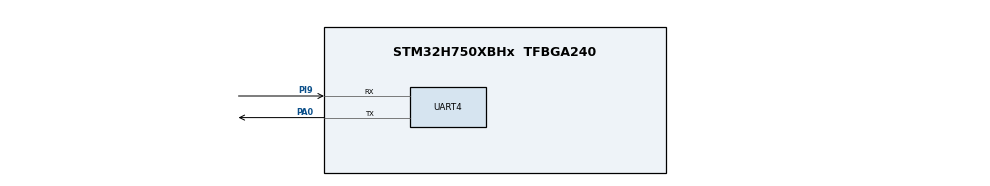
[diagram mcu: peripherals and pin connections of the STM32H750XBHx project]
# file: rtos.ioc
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FREERTOS.Tasks01=defaultTask,24,128,StartDefaultTask,Default,NULL,Dynamic,NULL,NULL
FREERTOS.configTICK_RATE_HZ=1000
FREERTOS.configUSE_NEWLIB_REENTRANT=1
Mcu.Family=STM32H7
Mcu.Name=STM32H750XBHx
Mcu.Package=TFBGA240
NVIC.PriorityGroup=NVIC_PRIORITYGROUP_4
NVIC.TIM6_DAC_IRQn=true\:15\:0\:false\:false\:true\:false\:false\:true\:true
NVIC.TimeBase=TIM6_DAC_IRQn
NVIC.TimeBaseIP=TIM6
NVIC.UART4_IRQn=true\:5\:0\:false\:false\:true\:true\:true\:true\:true
PA0.Mode=Asynchronous
PA0.Signal=UART4_TX
PA13\ (JTMS/SWDIO).Mode=Serial_Wire
PA13\ (JTMS/SWDIO).Signal=DEBUG_JTMS-SWDIO
PA14\ (JTCK/SWCLK).Mode=Serial_Wire
PA14\ (JTCK/SWCLK).Signal=DEBUG_JTCK-SWCLK
PH0-OSC_IN\ (PH0).Mode=HSE-External-Oscillator
PH0-OSC_IN\ (PH0).Signal=RCC_OSC_IN
PH1-OSC_OUT\ (PH1).Mode=HSE-External-Oscillator
PH1-OSC_OUT\ (PH1).Signal=RCC_OSC_OUT
PI9.Mode=Asynchronous
PI9.Signal=UART4_RX
ProjectManager.HeapSize=0x200
ProjectManager.StackSize=0x400
ProjectManager.TargetToolchain=STM32CubeIDE
RCC.ADCFreq_Value=400000000
RCC.APB1Freq_Value=100000000
RCC.APB2Freq_Value=100000000
RCC.APB3Freq_Value=100000000
RCC.APB4Freq_Value=100000000
RCC.CortexFreq_Value=400000000
RCC.D1PPRE=RCC_APB3_DIV2
RCC.D2PPRE1=RCC_APB1_DIV2
RCC.D2PPRE2=RCC_APB2_DIV2
RCC.D3PPRE=RCC_APB4_DIV2
RCC.DIVM1=5
RCC.DIVM2=5
RCC.DIVN1=160
RCC.DIVN2=160
RCC.DIVQ2=20
RCC.HCLKFreq_Value=200000000
RCC.HPRE=RCC_HCLK_DIV2
RCC.PLLSourceVirtual=RCC_PLLSOURCE_HSE
RCC.SYSCLKFreq_VALUE=400000000
RCC.SYSCLKSource=RCC_SYSCLKSOURCE_PLLCLK
RCC.USART234578CLockSelection=RCC_USART234578CLKSOURCE_PLL2
RCC.USBFreq_Value=400000000
VP_FREERTOS_VS_CMSIS_V2.Mode=CMSIS_V2
VP_SYS_VS_tim6.Mode=TIM6
board=custom

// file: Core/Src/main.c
/* USER CODE BEGIN Header */
/**
  ******************************************************************************
  * @file           : main.c
  * @brief          : Main program body
  ******************************************************************************
  * @attention
  *
  * Copyright (c) 2023 STMicroelectronics.
  * All rights reserved.
  *
  * This software is licensed under terms that can be found in the LICENSE file
  * in the root directory of this software component.
  * If no LICENSE file comes with this software, it is provided AS-IS.
  *
  ******************************************************************************
  */
/* USER CODE END Header */
#include "main.h"
#include "cmsis_os.h"
#include "usart.h"
#include "gpio.h"

/* USER CODE BEGIN Includes */
#include <string.h>
/* USER CODE END Includes */

/* USER CODE BEGIN PV */
extern volatile uint8_t uart4_rx_data;
extern volatile uint8_t uart4_rx_buff[100];
extern volatile uint8_t uart4_rx_cplt_flag;
extern volatile uint8_t uart4_tx_cplt_flag;
volatile uint8_t uart4_tx_buf[100];

/* USER CODE END PV */

void SystemClock_Config(void);
void MX_FREERTOS_Init(void);
/* USER CODE BEGIN PFP */
#ifdef __GNUC__
//With GCC, small printf (option LD Linker->Libraries->Small printf set to 'Yes') calls __io_putchar()
#define PUTCHAR_PROTOTYPE int __io_putchar(int ch)
#else
#define PUTCHAR_PROTOTYPE int fputc(int ch, FILE *f)
#endif /* __GNUC__ */
/* USER CODE END PFP */

int main(void)
{

  /* MCU Configuration--------------------------------------------------------*/

  /* Reset of all peripherals, Initializes the Flash interface and the Systick. */
  HAL_Init();

  /* Configure the system clock */
  SystemClock_Config();

  /* Initialize all configured peripherals */
  MX_GPIO_Init();
  MX_UART4_Init();
  /* USER CODE BEGIN 2 */
  printf("start main()\r\n");
  HAL_UART_Receive_IT(&huart4, &uart4_rx_data, 1);
  /* USER CODE END 2 */

  /* Init scheduler */
  osKernelInitialize();  /* Call init function for freertos objects (in freertos.c) */
  MX_FREERTOS_Init();

  /* Start scheduler */
  osKernelStart();
  /* We should never get here as control is now taken by the scheduler */
  /* Infinite loop */
  /* USER CODE BEGIN WHILE */
  //uint32_t pretime;
  //uint32_t curtime;
  while (1)
  {
/*
    if(uart4_rx_cplt_flag){
      pretime = HAL_GetTick();
      //printf("%s\r\n", uart_rx_buff);
      sprintf(uart4_tx_buf, "%s\r\n",uart4_rx_buff);
      HAL_UART_Transmit_IT(&huart4, uart4_tx_buf, strlen(uart4_tx_buf));
      curtime = HAL_GetTick();
      uart4_rx_cplt_flag = 0;
      printf("time : %d\r\n",curtime - pretime);
    }

    if(uart4_tx_cplt_flag){
      printf("time : %d\r\n",curtime - pretime);
      uart4_tx_cplt_flag = 0;
    }
*/

    /* USER CODE END WHILE */

  }
}

void SystemClock_Config(void)
{
  RCC_OscInitTypeDef RCC_OscInitStruct = {0};
  RCC_ClkInitTypeDef RCC_ClkInitStruct = {0};

  /** Supply configuration update enable
  */
  HAL_PWREx_ConfigSupply(PWR_LDO_SUPPLY);

  /** Configure the main internal regulator output voltage
  */
  __HAL_PWR_VOLTAGESCALING_CONFIG(PWR_REGULATOR_VOLTAGE_SCALE1);

  while(!__HAL_PWR_GET_FLAG(PWR_FLAG_VOSRDY)) {}

  /** Initializes the RCC Oscillators according to the specified parameters
  * in the RCC_OscInitTypeDef structure.
  */
  RCC_OscInitStruct.OscillatorType = RCC_OSCILLATORTYPE_HSE;
  RCC_OscInitStruct.HSEState = RCC_HSE_ON;
  RCC_OscInitStruct.PLL.PLLState = RCC_PLL_ON;
  RCC_OscInitStruct.PLL.PLLSource = RCC_PLLSOURCE_HSE;
  RCC_OscInitStruct.PLL.PLLM = 5;
  RCC_OscInitStruct.PLL.PLLN = 160;
  RCC_OscInitStruct.PLL.PLLP = 2;
  RCC_OscInitStruct.PLL.PLLQ = 2;
  RCC_OscInitStruct.PLL.PLLR = 2;
  RCC_OscInitStruct.PLL.PLLRGE = RCC_PLL1VCIRANGE_2;
  RCC_OscInitStruct.PLL.PLLVCOSEL = RCC_PLL1VCOWIDE;
  RCC_OscInitStruct.PLL.PLLFRACN = 0;
  if (HAL_RCC_OscConfig(&RCC_OscInitStruct) != HAL_OK)
  {
    Error_Handler();
  }

  /** Initializes the CPU, AHB and APB buses clocks
  */
  RCC_ClkInitStruct.ClockType = RCC_CLOCKTYPE_HCLK|RCC_CLOCKTYPE_SYSCLK
                              |RCC_CLOCKTYPE_PCLK1|RCC_CLOCKTYPE_PCLK2
                              |RCC_CLOCKTYPE_D3PCLK1|RCC_CLOCKTYPE_D1PCLK1;
  RCC_ClkInitStruct.SYSCLKSource = RCC_SYSCLKSOURCE_PLLCLK;
  RCC_ClkInitStruct.SYSCLKDivider = RCC_SYSCLK_DIV1;
  RCC_ClkInitStruct.AHBCLKDivider = RCC_HCLK_DIV2;
  RCC_ClkInitStruct.APB3CLKDivider = RCC_APB3_DIV2;
  RCC_ClkInitStruct.APB1CLKDivider = RCC_APB1_DIV2;
  RCC_ClkInitStruct.APB2CLKDivider = RCC_APB2_DIV2;
  RCC_ClkInitStruct.APB4CLKDivider = RCC_APB4_DIV2;

  if (HAL_RCC_ClockConfig(&RCC_ClkInitStruct, FLASH_LATENCY_2) != HAL_OK)
  {
    Error_Handler();
  }
}

/* USER CODE BEGIN 4 */
PUTCHAR_PROTOTYPE
{
/* Place your implementation of fputc here */
/* e.g. write a character to the USART3 and Loop until the end of transmission */
  HAL_UART_Transmit(&huart4, (uint8_t*) &ch, 1, 0xFFFF);
  return ch;
}
/* USER CODE END 4 */

void HAL_TIM_PeriodElapsedCallback(TIM_HandleTypeDef *htim)
{
  if (htim->Instance == TIM6) {
    HAL_IncTick();
  }
}

void Error_Handler(void)
{
  __disable_irq();
  while (1)
  {
  }
}

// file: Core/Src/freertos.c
/* USER CODE BEGIN Header */
/**
  ******************************************************************************
  * File Name          : freertos.c
  * Description        : Code for freertos applications
  ******************************************************************************
  * @attention
  *
  * Copyright (c) 2023 STMicroelectronics.
  * All rights reserved.
  *
  * This software is licensed under terms that can be found in the LICENSE file
  * in the root directory of this software component.
  * If no LICENSE file comes with this software, it is provided AS-IS.
  *
  ******************************************************************************
  */
/* USER CODE END Header */

#include "FreeRTOS.h"
#include "task.h"
#include "main.h"
#include "cmsis_os.h"

/* Definitions for defaultTask */
osThreadId_t defaultTaskHandle;
const osThreadAttr_t defaultTask_attributes = {
  .name = "defaultTask",
  .stack_size = 128 * 4,
  .priority = (osPriority_t) osPriorityNormal,
};
/* Definitions for myTask02 */
osThreadId_t myTask02Handle;
const osThreadAttr_t myTask02_attributes = {
  .name = "myTask02",
  .stack_size = 128 * 4,
  .priority = (osPriority_t) osPriorityLow,
};
/* Definitions for myTask03 */
osThreadId_t myTask03Handle;
const osThreadAttr_t myTask03_attributes = {
  .name = "myTask03",
  .stack_size = 128 * 4,
  .priority = (osPriority_t) osPriorityLow,
};

void StartDefaultTask(void *argument);
void StartTask02(void *argument);
void StartTask03(void *argument);

void MX_FREERTOS_Init(void); /* (MISRA C 2004 rule 8.1) */

void MX_FREERTOS_Init(void) {

  /* Create the thread(s) */
  /* creation of defaultTask */
  defaultTaskHandle = osThreadNew(StartDefaultTask, NULL, &defaultTask_attributes);

  /* creation of myTask02 */
  myTask02Handle = osThreadNew(StartTask02, NULL, &myTask02_attributes);

  /* creation of myTask03 */
  myTask03Handle = osThreadNew(StartTask03, NULL, &myTask03_attributes);

}

void StartDefaultTask(void *argument)
{
  /* USER CODE BEGIN StartDefaultTask */
  /* Infinite loop */
  for(;;)
  {
    //printf("task 1\r\n");
    HAL_GPIO_TogglePin(GPIOC, GPIO_PIN_6);
    osDelay(1000);
  }
  /* USER CODE END StartDefaultTask */
}

void StartTask02(void *argument)
{
  /* USER CODE BEGIN StartTask02 */
  /* Infinite loop */
  for(;;)
  {
    HAL_GPIO_TogglePin(GPIOG, GPIO_PIN_7);
    osDelay(2000);
  }
  /* USER CODE END StartTask02 */
}

void StartTask03(void *argument)
{
  /* USER CODE BEGIN StartTask03 */
  /* Infinite loop */
  for(;;)
  {
    HAL_GPIO_TogglePin(GPIOH, GPIO_PIN_8);
    osDelay(3000);
  }
  /* USER CODE END StartTask03 */
}
